# M55M1 register map
File version: 1.0
Registers are 32-bit, read-write, reset 0x0 unless marked. A register's access mark holds for its fields unless they carry their own. Offsets are from the block's base; [hi:lo] are bit positions; {n}, {i} and the like mark numbered series; 'fields as' and 'values as' point back to an identical list.

## USBD_NS — USBD Register Map
Base 0x5025C000
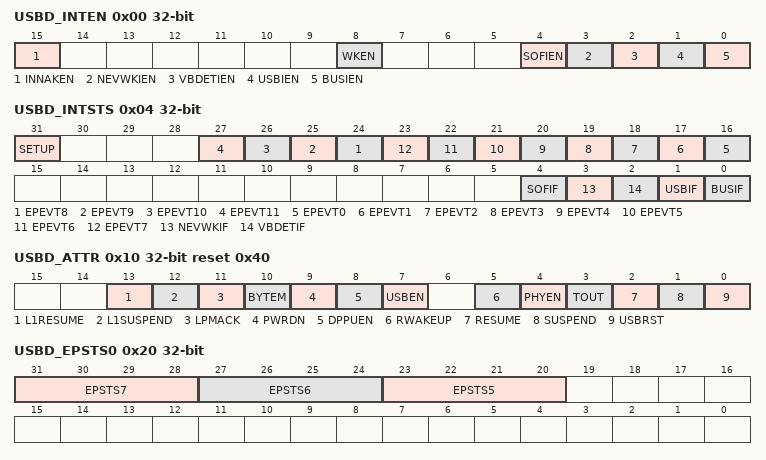
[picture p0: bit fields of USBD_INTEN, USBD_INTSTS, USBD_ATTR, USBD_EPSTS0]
0x00 USBD_INTEN — USB Device Interrupt Enable Register
  [15] INNAKEN — Active NAK Function and Its Status in IN Token
    0=When device responds NAK after receiving IN token, IN NAK status will not be updated to USBD_EPSTS0 and USBD_EPSTS1register, so that the USB interrupt event will not be asserted; 1=IN NAK status will be updated to USBD_EPSTS0 and USBD_EPSTS1 register and the USB interrupt event will be asserted, when the device responds NAK after receiving IN token
  [8] WKEN — Wake-up Function Enable Bit
    0=USB wake-up function Disabled; 1=USB wake-up function Enabled
  [4] SOFIEN — Start of Frame Interrupt Enable Bit
    0=SOF Interrupt Disabled; 1=SOF Interrupt Enabled
  [3] NEVWKIEN — USB No-event-wake-up Interrupt Enable Bit
    0=No-event-wake-up Interrupt Disabled; 1=No-event-wake-up Interrupt Enabled
  [2] VBDETIEN — VBUS Detection Interrupt Enable Bit
    0=VBUS detection Interrupt Disabled; 1=VBUS detection Interrupt Enabled
  [1] USBIEN — USB Event Interrupt Enable Bit
    0=USB event interrupt Disabled; 1=USB event interrupt Enabled
  [0] BUSIEN — Bus Event Interrupt Enable Bit
    0=BUS event interrupt Disabled; 1=BUS event interrupt Enabled
0x04 USBD_INTSTS — USB Device Interrupt Event Status Register
  [31] SETUP — Setup Event Status
    0=No Setup event; 1=Setup event occurred, cleared by writing 1 to USBD_INTSTS[31]
  [n+16] EPEVT{n} (n=8..11) — Endpoint {n}'s USB Event Status
    0=No event occurred in endpoint {n}; 1=USB event occurred on Endpoint {n}. Check USBD_EPSTS1[{4n-29}:{4n-32}] to know which kind of USB event was occurred, cleared by writing 1 to USBD_INTSTS[{n+16}] or USBD_EPINTSTS[{n}] or USBD_INTSTS[1]
  [n+16] EPEVT{n} (n=0..7) — Endpoint {n}'s USB Event Status
    0=No event occurred in endpoint {n}; 1=USB event occurred on Endpoint {n}. Check USBD_EPSTS0[{4n+3}:{4n}] to know which kind of USB event was occurred, cleared by writing 1 to USBD_INTSTS[{n+16}] or USBD_EPINTSTS[{n}] or USBD_INTSTS[1]
  [4] SOFIF — Start of Frame Interrupt Status
    0=SOF event did not occur; 1=SOF event occurred, cleared by writing 1 to USBD_INTSTS[4]
  [3] NEVWKIF — No-event-wake-up Interrupt Status
    0=NEVWK event did not occur; 1=No-event-wake-up event occurred, cleared by writing 1 to USBD_INTSTS[3]
  [2] VBDETIF — VBUS Detection Interrupt Status
    0=There is not attached/detached event in the USB; 1=There is attached/detached event in the USB bus and it is cleared by writing 1 to USBD_INTSTS[2]
  [1] USBIF — USB Event Interrupt Status. The USB event includes the SETUP Token, IN Token, OUT ACK, ISO IN, or ISO OUT events in the bus.
    0=No USB event occurred; 1=USB event occurred. Check EPSTS0~25 in USBD_EPSTS0~3 to know which kind of USB event was occurred, cleared by writing 1 to USBD_INTSTS[1] or USBD_INTSTS[27:16] or USBD_EPINTSTS[24:0] and SETUP (USBD_INTSTS[31])
  [0] BUSIF — BUS Interrupt Status. The BUS event means that there is one of the suspense or the resume function in the bus.
    0=No BUS event occurred; 1=Bus event occurred; check USBD_ATTR[3:0] to know which kind of bus event was occurred, cleared by writing 1 to USBD_INTSTS[0]
0x08 USBD_FADDR — USB Device Function Address Register
  [6:0] FADDR — USB device function address
0x0C USBD_EPSTS ro — USB Device Endpoint Status Register
  [7] OV — Overrun. It indicates that the received data is over the maximum payload number or not.
    0=No overrun; 1=Out Data is more than the Max Payload in MXPLD register or the Setup Data is more than 8 bytes
0x10 USBD_ATTR reset 0x40 — USB Device Bus Status and Attribution Register
  [13] L1RESUME ro — LPM L1 Resume (Read Only)
    0=Bus no LPM L1 state resume; 1=LPM L1 state resume from LPM L1 state suspend
  [12] L1SUSPEND ro — LPM L1 Suspend (Read Only)
    0=Bus no L1 state suspend; 1=This bit is set by the hardware when LPM command to enter the L1 state is successfully received and acknowledged
  [11] LPMACK — LPM Token Acknowledge Enable Bit
    0=The valid LPM Token will be NYET; 1=The valid LPM Token will be ACK
  [10] BYTEM — CPU Access USB SRAM Size Mode Selection
    0=Word mode: The size of the transfer from CPU to USB SRAM can be Word only; 1=Byte mode: The size of the transfer from CPU to USB SRAM can be Byte only
  [9] PWRDN — Power-down PHY Transceiver, Low Active
    0=Power-down related circuit of PHY transceiver; 1=Turn-on related circuit of PHY transceiver
  [8] DPPUEN — Pull-up Resistor on USB_DP Enable Bit
    0=Pull-up resistor in USB_D+ bus Disabled; 1=Pull-up resistor in USB_D+ bus Active
  [7] USBEN — USB Controller Enable Bit
    0=USB Controller Disabled; 1=USB Controller Enabled
  [5] RWAKEUP — Remote Wake-up
    0=Release the USB bus from K state; 1=Force USB bus to K (USB_D+ low, USB_D- high) state, used for remote wake-up
  [4] PHYEN — PHY Transceiver Function Enable Bit
    0=PHY transceiver function Disabled; 1=PHY transceiver function Enabled
  [3] TOUT ro — Time-out Status (Read Only)
    0=No time-out; 1=No Bus response more than 18 bits time
  [2] RESUME ro — Resume Status (Read Only)
    0=No bus resume; 1=Resume from suspend
  [1] SUSPEND ro — Suspend Status (Read Only)
    0=Bus no suspend; 1=Bus idle more than 3ms, either cable is plugged-out or host is sleeping
  [0] USBRST ro — USB Reset Status (Read Only)
    0=Bus no reset; 1=Bus reset when SE0 (single-ended 0) more than 2.5us
0x14 USBD_VBUSDET ro — USB Device VBUS Detection Register
  [0] VBUSDET — Device VBUS Detection
    0=Controller is not attached to the USB host; 1=Controller is attached to the USB host
0x18 USBD_STBUFSEG — SETUP Token Buffer Segmentation Register
  [10:3] STBUFSEG — SETUP Token Buffer Segmentation. It is used to indicate the offset address for the SETUP token with the USB Device SRAM starting address. The effective starting address is. USBD_SRAM address + {STBUFSE.G. 3'b000} Note: It is used for SETUP token only.
0x20 USBD_EPSTS0 ro — USB Device Endpoint Status Register 0
  [all] fields
    0=In ACK; 1=In NAK; 2=Out Packet Data0 ACK; 6=Out Packet Data1 ACK; 7=Isochronous transfer end
  [31:28] EPSTS7 — Endpoint 7 Status. These bits are used to indicate the current status of this endpoint.
  [27:24] EPSTS6 — Endpoint 6 Status. These bits are used to indicate the current status of this endpoint.
  [23:20] EPSTS5 — Endpoint 5 Status. These bits are used to indicate the current status of this endpoint.
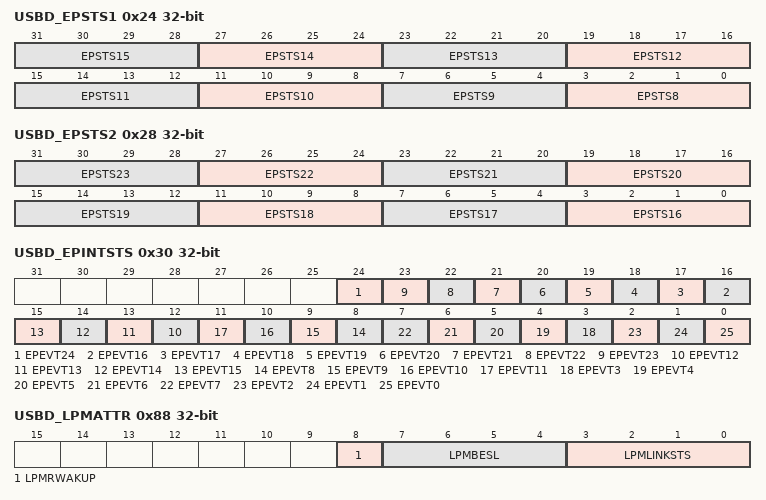
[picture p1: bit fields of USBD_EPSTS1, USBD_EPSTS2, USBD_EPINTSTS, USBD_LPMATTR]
0x24 USBD_EPSTS1 ro — USB Device Endpoint Status Register 1
  [all] fields
    values as the fields of USBD_EPSTS0
  [4n-29:4n-32] EPSTS{n} (n=8..15) — Endpoint {n} Status. These bits are used to indicate the current status of this endpoint.
0x28 USBD_EPSTS2 ro — USB Device Endpoint Status Register 2
  [all] fields
    values as the fields of USBD_EPSTS0
  [4n-61:4n-64] EPSTS{n} (n=16..23) — Endpoint {n} Status. These bits are used to indicate the current status of this endpoint.
0x2C USBD_EPSTS3 ro — USB Device Endpoint Status Register 3
  [3:0] EPSTS24 — Endpoint 24 Status. These bits are used to indicate the current status of this endpoint.
    values as the fields of USBD_EPSTS0
0x30 USBD_EPINTSTS — USB Device Endpoint Interrupt Event Status Register
  [24] EPEVT24 — Endpoint 24's USB Event Status
    0=No event occurred in endpoint 24; 1=USB event occurred on Endpoint 24. Check USBD_EPSTS3[3:0] to know which kind of USB event was occurred, cleared by writing 1 to USBD_EPINTSTS[24] or USBD_INTSTS[1]
  [n] EPEVT{n} (n=16..23) — Endpoint {n}'s USB Event Status
    0=No event occurred in endpoint {n}; 1=USB event occurred on Endpoint {n}. Check USBD_EPSTS2[{4n-61}:{4n-64}] to know which kind of USB event was occurred, cleared by writing 1 to USBD_EPINTSTS[{n}] or USBD_INTSTS[1]
  [n] EPEVT{n} (n=12..15) — Endpoint {n}'s USB Event Status
    0=No event occurred in endpoint {n}; 1=USB event occurred on Endpoint {n}. Check USBD_EPSTS1[{4n-33}:{4n-36}] to know which kind of USB event was occurred, cleared by writing 1 to USBD_EPINTSTS[{n}] or USBD_INTSTS[1]
  [n] EPEVT{n} (n=8..11) — Endpoint {n}'s USB Event Status
    0=No event occurred in endpoint {n}; 1=USB event occurred on Endpoint {n}. Check USBD_EPSTS1[{4n-29}:{4n-32}] to know which kind of USB event was occurred, cleared by writing 1 to USBD_EPINTSTS[{n}] or USBD_INTSTS[{n+16}] or USBD_INTSTS[1]
  [n] EPEVT{n} (n=3..7) — Endpoint {n}'s USB Event Status
    0=No event occurred in endpoint {n}; 1=USB event occurred on Endpoint {n}. Check USBD_EPSTS0[{4n+3}:{4n}] to know which kind of USB event was occurred, cleared by writing 1 to USBD_EPINTSTS[{n}] or USBD_INTSTS[{n+16}] or USBD_INTSTS[1]
  [2] EPEVT2 — Endpoint 2's USB Event Status
    0=No event occurred in endpoint 2; 1=USB event occurred on Endpoint 2. Check USBD_EPSTS0[11:8] to know which kind of USB event was occurred, cleared by writing 1 to USBD_EPINTSTS[2] or USBD_EPINTSTS[2] or USBD_INTSTS[18] or USBD_INTSTS[1]
  [1] EPEVT1 — Endpoint 1's USB Event Status
    0=No event occurred in endpoint 1; 1=USB event occurred on Endpoint 1. Check USBD_EPSTS0[7:4] to know which kind of USB event was occurred, cleared by writing 1 to USBD_EPINTSTS[1] or USBD_INTSTS[17] or USBD_INTSTS[1]
  [0] EPEVT0 — Endpoint 0's USB Event Status
    0=No event occurred in endpoint 0; 1=USB event occurred on Endpoint 0. Check USBD_EPSTS0[3:0] to know which kind of USB event was occurred, cleared by writing 1 to USBD_EPINTSTS[0] or USBD_INTSTS[16] or USBD_INTSTS[1]
0x88 USBD_LPMATTR ro — USB LPM Attribution Register
  [8] LPMRWAKUP — LPM Remote Wakeup. This bit contains the bRemoteWake value received with last ACK LPM Token
  [7:4] LPMBESL — LPM Best Effort Service Latency. These bits contain the BESL value received with last ACK LPM Token
  [3:0] LPMLINKSTS — LPM Link State. These bits contain the bLinkState received with last ACK LPM Token
0x8C USBD_FN ro (reset mask 0xFFFFF000) — USB Frame Number Register
  [10:0] FN — Frame Number. These bits contain the 11 bits frame number in the last received SOF packet.
0x90 USBD_SE0 reset 0x1 — USB Device Drive SE0 Control Register
  [0] SE0 — Drive Single Ended Zero in USB Bus. The Single Ended Zero (SE0) is when both lines (USB_D+ and USB_D-) are being pulled low.
    0=Normal operation; 1=Force USB PHY transceiver to drive SE0
{0x500+0x10*i} USBD_BUFSEG{i} (i=0..24) — Endpoint {i} Buffer Segmentation Register
  [10:3] BUFSEG — Endpoint Buffer Segmentation. It is used to indicate the offset address for each endpoint with the USB SRAM starting address The effective starting address of the endpoint is. USBD_SRAM address + {BUFSE.G. 3'b000} Refer to the section 6.44.5.7 for the endpoint SRAM structure and its description.
{0x504+0x10*i} USBD_MXPLD{i} (i=0..24) — Endpoint {i} Maximal Payload Register
  [10:0] MXPLD — Maximal Payload. Define the data length which is transmitted to host (IN token) or the actual data length which is received from the host (OUT token). It also used to indicate that the endpoint is ready to be transmitted in IN token or received in OUT token. (1) When the register is written by CPU, For IN token, the value of MXPLD is used to define the data length to be transmitted and indicate the data buffer is ready. For OUT token, it means that the controller is ready to receive data from the host and the value of MXPLD is the maximal data length comes from host. (2) When the register is read by CPU, For IN token, the value of MXPLD is indicated by the data length be transmitted to host. For OUT token, the value of MXPLD is indicated the actual data length receiving from host. Note: Once MXPLD is written, the data packets will be transmitted/received immediately after IN/OUT token arrived.
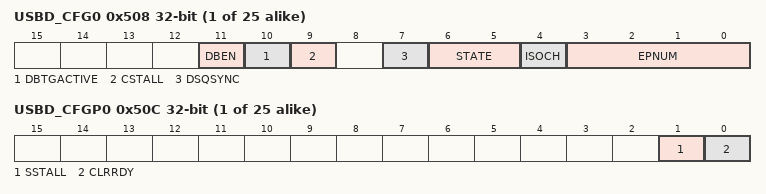
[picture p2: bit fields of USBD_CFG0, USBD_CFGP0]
{0x508+0x10*i} USBD_CFG{i} (i=0..24) — Endpoint {i} Configuration Register
  [11] DBEN — Double Buffer Enable Bit
    0=Single buffer mode; 1=Double buffer mode
  [10] DBTGACTIVE — Double Buffer Toggle Active Bit
    0=Inactive in double buffer mode; 1=Active in double buffer mode
  [9] CSTALL — Clear STALL Response
    0=Disable the device to clear the STALL handshake in setup stage; 1=Clear the device to response STALL handshake in setup stage
  [7] DSQSYNC — Data Sequence Synchronization
    0=DATA0 PID; 1=DATA1 PID
  [6:5] STATE — Endpoint State
    0=Endpoint is Disabled; 1=Out endpoint; 2=IN endpoint; 3=Undefined
  [4] ISOCH — Isochronous Endpoint. This bit is used to set the endpoint as Isochronous endpoint, no handshake.
    0=No Isochronous endpoint; 1=Isochronous endpoint
  [3:0] EPNUM — Endpoint Number. These bits are used to define the endpoint number of the current endpoint.
{0x50C+0x10*i} USBD_CFGP{i} (i=0..24) — Endpoint {i} Set Stall and Clear In/Out Ready Control Register
  [1] SSTALL — Set STALL
    0=Disable the device to response STALL; 1=Set the device to respond STALL automatically
  [0] CLRRDY — Clear Ready. When the USBD_MXPLD0~24 register is set by user, it means that the endpoint is ready to transmit or receive data. If the user wants to disable this transaction before the transaction start, users can set this bit to 1 to disable it and it is automatically cleared to 0. For IN token, write '1' to clear the IN token had ready to transmit the data to USB. For OUT token, write '1' to clear the OUT token had ready to receive the data from USB. This bit is written 1 only and is always 0 when it is read back.
